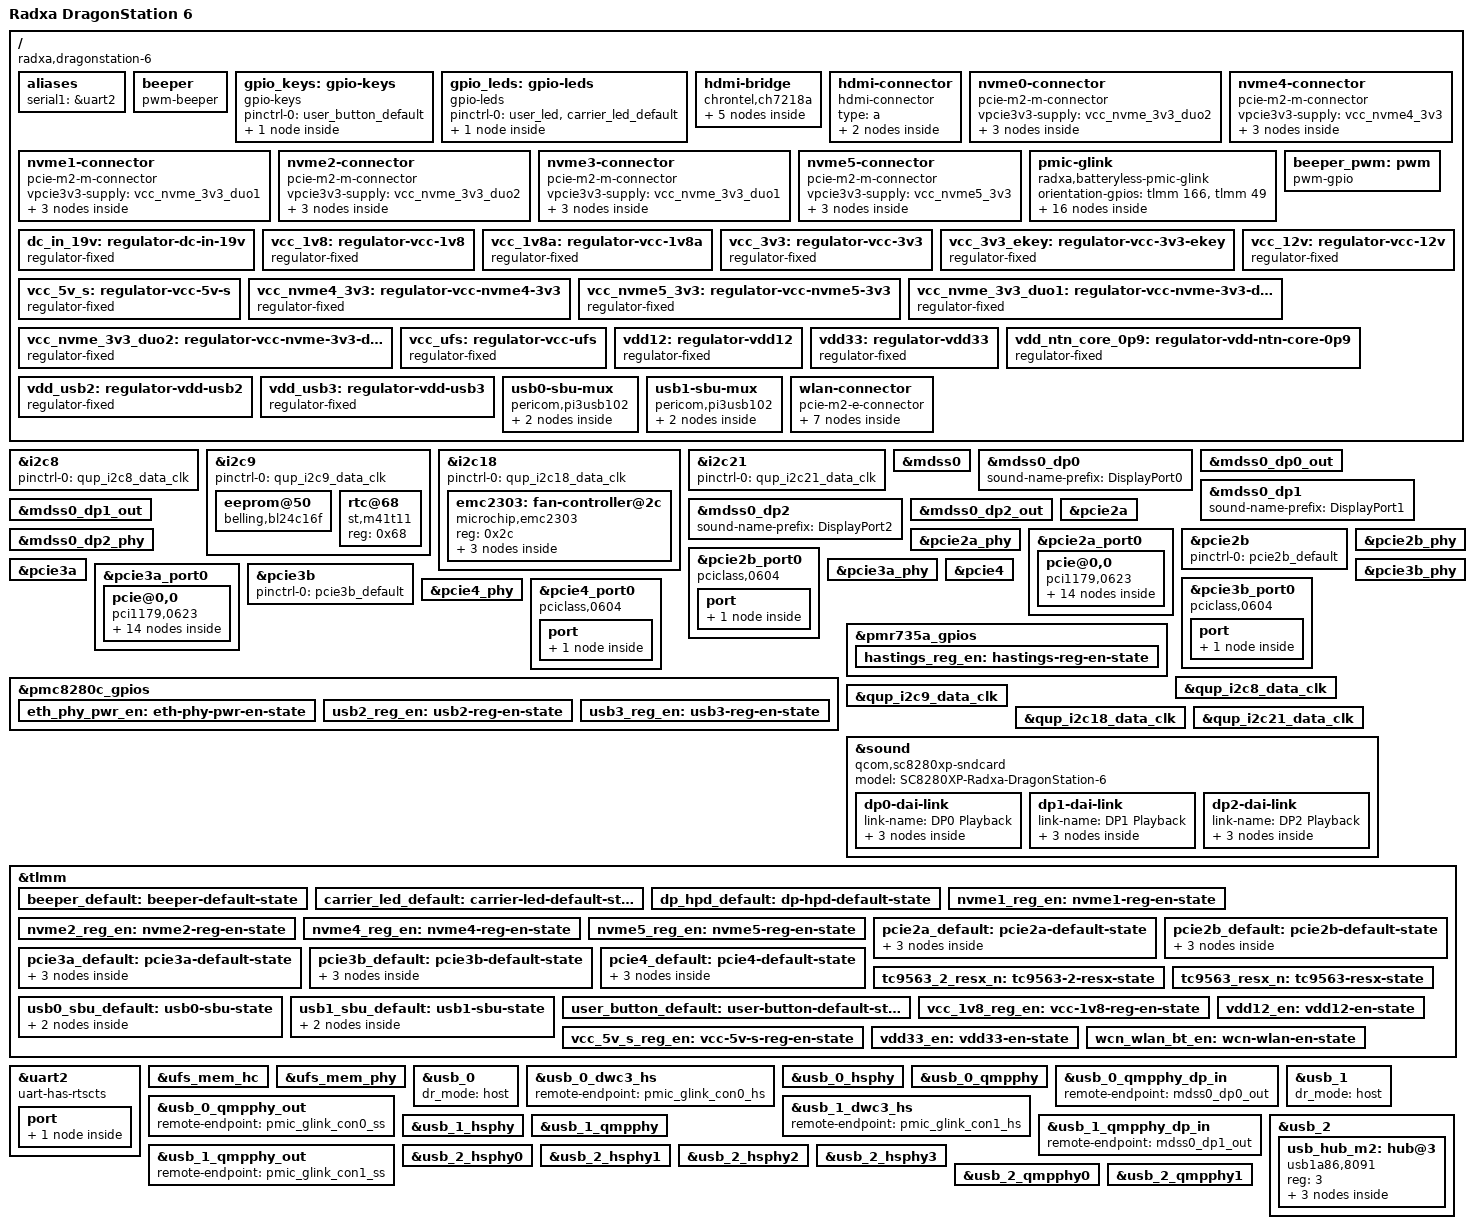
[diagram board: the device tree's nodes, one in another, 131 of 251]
// SPDX-License-Identifier: BSD-3-Clause
/*
 * Copyright (c) 2026 Radxa Computer (Shenzhen) Co., Ltd.
 */

/dts-v1/;

#include <dt-bindings/input/input.h>
#include <dt-bindings/leds/common.h>
#include "sc8280xp-radxa-rcore-q8280.dtsi"

/ {
	model = "Radxa DragonStation 6";
	compatible = "radxa,dragonstation-6", "radxa,rcore-q8280", "qcom,sc8280xp";
	chassis-type = "embedded";

	aliases {
		serial1 = &uart2;
	};

	beeper {
		compatible = "pwm-beeper";
		pwms = <&beeper_pwm 0 500000 0>;
		amp-supply = <&vcc_3v3>;
		beeper-hz = <2000>;
	};

	gpio_keys: gpio-keys {
		compatible = "gpio-keys";
		pinctrl-0 = <&user_button_default>;
		pinctrl-names = "default";

		user-button {
			label = "User Button";
			gpios = <&tlmm 114 GPIO_ACTIVE_LOW>;
			linux,code = <KEY_PROG1>;
			debounce-interval = <20>;
		};
	};

	gpio_leds: gpio-leds {
		compatible = "gpio-leds";
		pinctrl-0 = <&user_led>, <&carrier_led_default>;
		pinctrl-names = "default";

		user-led2 {
			label = "carrier:blue:status";
			color = <LED_COLOR_ID_BLUE>;
			function = LED_FUNCTION_STATUS;
			gpios = <&tlmm 115 GPIO_ACTIVE_HIGH>;
			default-state = "off";
		};
	};

	hdmi-bridge {
		compatible = "chrontel,ch7218a";
		vdd-supply = <&vcc_5v_s>;
		pinctrl-0 = <&dp_hpd_default>;
		pinctrl-names = "default";

		ports {
			#address-cells = <1>;
			#size-cells = <0>;

			port@0 {
				reg = <0>;

				hdmi_bridge_dp_in: endpoint {
					remote-endpoint = <&mdss0_dp2_out>;
				};
			};

			port@1 {
				reg = <1>;

				hdmi_bridge_frl_out: endpoint {
					remote-endpoint = <&hdmi_con>;
				};
			};
		};
	};

	hdmi-connector {
		compatible = "hdmi-connector";
		type = "a";

		port {
			hdmi_con: endpoint {
				remote-endpoint = <&hdmi_bridge_frl_out>;
			};
		};
	};

	/* J27 M-key */
	nvme0-connector {
		compatible = "pcie-m2-m-connector";
		vpcie3v3-supply = <&vcc_nvme_3v3_duo2>;

		ports {
			#address-cells = <1>;
			#size-cells = <0>;

			port@0 {
				reg = <0>;

				nvme0_pcie_ep: endpoint {
					remote-endpoint = <&pcie2b_ep>;
				};
			};
		};
	};

	/* J28 M-key */
	nvme1-connector {
		compatible = "pcie-m2-m-connector";
		vpcie3v3-supply = <&vcc_nvme_3v3_duo1>;

		ports {
			#address-cells = <1>;
			#size-cells = <0>;

			port@0 {
				reg = <0>;

				nvme1_pcie_ep: endpoint {
					remote-endpoint = <&qps615_1_dsp1_ep>;
				};
			};
		};
	};

	/* J29 M-key */
	nvme2-connector {
		compatible = "pcie-m2-m-connector";
		vpcie3v3-supply = <&vcc_nvme_3v3_duo2>;

		ports {
			#address-cells = <1>;
			#size-cells = <0>;

			port@0 {
				reg = <0>;

				nvme2_pcie_ep: endpoint {
					remote-endpoint = <&pcie3b_ep>;
				};
			};
		};
	};

	/* J30 M-key */
	nvme3-connector {
		compatible = "pcie-m2-m-connector";
		vpcie3v3-supply = <&vcc_nvme_3v3_duo1>;

		ports {
			#address-cells = <1>;
			#size-cells = <0>;

			port@0 {
				reg = <0>;

				nvme3_pcie_ep: endpoint {
					remote-endpoint = <&qps615_2_dsp1_ep>;
				};
			};
		};
	};

	/* J31 M-key */
	nvme4-connector {
		compatible = "pcie-m2-m-connector";
		vpcie3v3-supply = <&vcc_nvme4_3v3>;

		ports {
			#address-cells = <1>;
			#size-cells = <0>;

			port@0 {
				reg = <0>;

				nvme4_pcie_ep: endpoint {
					remote-endpoint = <&qps615_2_dsp2_ep>;
				};
			};
		};
	};

	/* J32 M-key */
	nvme5-connector {
		compatible = "pcie-m2-m-connector";
		vpcie3v3-supply = <&vcc_nvme5_3v3>;

		ports {
			#address-cells = <1>;
			#size-cells = <0>;

			port@0 {
				reg = <0>;

				nvme5_pcie_ep: endpoint {
					remote-endpoint = <&qps615_1_dsp2_ep>;
				};
			};
		};
	};

	pmic-glink {
		compatible = "radxa,batteryless-pmic-glink",
			     "qcom,sc8280xp-pmic-glink", "qcom,pmic-glink";
		#address-cells = <1>;
		#size-cells = <0>;
		orientation-gpios = <&tlmm 166 GPIO_ACTIVE_HIGH>,
				    <&tlmm 49 GPIO_ACTIVE_HIGH>;

		connector@0 {
			compatible = "usb-c-connector";
			reg = <0>;
			power-role = "dual";
			data-role = "dual";

			ports {
				#address-cells = <1>;
				#size-cells = <0>;

				port@0 {
					reg = <0>;

					pmic_glink_con0_hs: endpoint {
						remote-endpoint = <&usb_0_dwc3_hs>;
					};
				};

				port@1 {
					reg = <1>;

					pmic_glink_con0_ss: endpoint {
						remote-endpoint = <&usb_0_qmpphy_out>;
					};
				};

				port@2 {
					reg = <2>;

					pmic_glink_con0_sbu: endpoint {
						remote-endpoint = <&usb0_sbu_mux>;
					};
				};
			};
		};

		connector@1 {
			compatible = "usb-c-connector";
			reg = <1>;
			power-role = "dual";
			data-role = "dual";

			ports {
				#address-cells = <1>;
				#size-cells = <0>;

				port@0 {
					reg = <0>;

					pmic_glink_con1_hs: endpoint {
						remote-endpoint = <&usb_1_dwc3_hs>;
					};
				};

				port@1 {
					reg = <1>;

					pmic_glink_con1_ss: endpoint {
						remote-endpoint = <&usb_1_qmpphy_out>;
					};
				};

				port@2 {
					reg = <2>;

					pmic_glink_con1_sbu: endpoint {
						remote-endpoint = <&usb1_sbu_mux>;
					};
				};
			};
		};
	};

	beeper_pwm: pwm {
		compatible = "pwm-gpio";
		gpios = <&tlmm 174 GPIO_ACTIVE_HIGH>;
		#pwm-cells = <3>;
		pinctrl-0 = <&beeper_default>;
		pinctrl-names = "default";
	};

	dc_in_19v: regulator-dc-in-19v {
		compatible = "regulator-fixed";
		regulator-name = "dc_in_19v";
		regulator-min-microvolt = <19000000>;
		regulator-max-microvolt = <19000000>;
		regulator-always-on;
	};

	vcc_1v8: regulator-vcc-1v8 {
		compatible = "regulator-fixed";
		regulator-name = "vcc_1v8";
		regulator-min-microvolt = <1800000>;
		regulator-max-microvolt = <1800000>;
		vin-supply = <&vcc_1v8a>;
		gpio = <&tlmm 161 GPIO_ACTIVE_HIGH>;
		enable-active-high;
		/* Longer delay for I2C pull-up to stabilize */
		startup-delay-us = <50000>;
		pinctrl-0 = <&vcc_1v8_reg_en>;
		pinctrl-names = "default";
	};

	vcc_1v8a: regulator-vcc-1v8a {
		compatible = "regulator-fixed";
		regulator-name = "vcc_1v8a";
		regulator-min-microvolt = <1800000>;
		regulator-max-microvolt = <1800000>;
		gpio = <&pmc8280c_gpios 4 GPIO_ACTIVE_HIGH>;
		enable-active-high;
		regulator-always-on;
		regulator-boot-on;
		startup-delay-us = <1000>;
		pinctrl-0 = <&eth_phy_pwr_en>;
		pinctrl-names = "default";
	};

	vcc_3v3: regulator-vcc-3v3 {
		compatible = "regulator-fixed";
		regulator-name = "vcc_3v3";
		regulator-min-microvolt = <3300000>;
		regulator-max-microvolt = <3300000>;
		regulator-always-on;
	};

	vcc_3v3_ekey: regulator-vcc-3v3-ekey {
		compatible = "regulator-fixed";
		regulator-name = "vcc_3v3_ekey";
		regulator-min-microvolt = <3300000>;
		regulator-max-microvolt = <3300000>;
		gpio = <&pmr735a_gpios 1 GPIO_ACTIVE_HIGH>;
		enable-active-high;
		startup-delay-us = <3000>;
		pinctrl-0 = <&hastings_reg_en>;
		pinctrl-names = "default";
		regulator-boot-on;
	};

	vcc_5v_s: regulator-vcc-5v-s {
		compatible = "regulator-fixed";
		regulator-name = "vcc_5v_s";
		regulator-min-microvolt = <5000000>;
		regulator-max-microvolt = <5000000>;
		gpio = <&tlmm 159 GPIO_ACTIVE_HIGH>;
		enable-active-high;
		startup-delay-us = <250000>;
		off-on-delay-us = <150000>;
		pinctrl-0 = <&vcc_5v_s_reg_en>;
		pinctrl-names = "default";
	};

	vcc_12v: regulator-vcc-12v {
		compatible = "regulator-fixed";
		regulator-name = "vcc_12v";
		regulator-min-microvolt = <12000000>;
		regulator-max-microvolt = <12000000>;
		regulator-always-on;
		vin-supply = <&dc_in_19v>;
	};

	vcc_nvme4_3v3: regulator-vcc-nvme4-3v3 {
		compatible = "regulator-fixed";
		regulator-name = "vcc_nvme4_3v3";
		regulator-min-microvolt = <3300000>;
		regulator-max-microvolt = <3300000>;
		gpio = <&tlmm 201 GPIO_ACTIVE_HIGH>;
		enable-active-high;
		startup-delay-us = <3000>;
		pinctrl-0 = <&nvme4_reg_en>;
		pinctrl-names = "default";
		regulator-boot-on;
		vin-supply = <&vcc_3v3>;
	};

	vcc_nvme5_3v3: regulator-vcc-nvme5-3v3 {
		compatible = "regulator-fixed";
		regulator-name = "vcc_nvme5_3v3";
		regulator-min-microvolt = <3300000>;
		regulator-max-microvolt = <3300000>;
		gpio = <&tlmm 135 GPIO_ACTIVE_HIGH>;
		enable-active-high;
		startup-delay-us = <3000>;
		pinctrl-0 = <&nvme5_reg_en>;
		pinctrl-names = "default";
		regulator-boot-on;
		vin-supply = <&vcc_3v3>;
	};

	vcc_nvme_3v3_duo1: regulator-vcc-nvme-3v3-duo1 {
		compatible = "regulator-fixed";
		regulator-name = "vcc_nvme_3v3_duo1";
		regulator-min-microvolt = <3300000>;
		regulator-max-microvolt = <3300000>;
		gpio = <&tlmm 213 GPIO_ACTIVE_HIGH>;
		enable-active-high;
		startup-delay-us = <3000>;
		pinctrl-0 = <&nvme1_reg_en>;
		pinctrl-names = "default";
		vin-supply = <&dc_in_19v>;
	};

	vcc_nvme_3v3_duo2: regulator-vcc-nvme-3v3-duo2 {
		compatible = "regulator-fixed";
		regulator-name = "vcc_nvme_3v3_duo2";
		regulator-min-microvolt = <3300000>;
		regulator-max-microvolt = <3300000>;
		gpio = <&tlmm 212 GPIO_ACTIVE_HIGH>;
		enable-active-high;
		startup-delay-us = <3000>;
		pinctrl-0 = <&nvme2_reg_en>;
		pinctrl-names = "default";
		vin-supply = <&dc_in_19v>;
	};

	/* This regulator is part of the removable UFS module on J17. */
	vcc_ufs: regulator-vcc-ufs {
		compatible = "regulator-fixed";
		regulator-name = "vcc_ufs";
		regulator-min-microvolt = <2480000>;
		regulator-max-microvolt = <2480000>;
		vin-supply = <&vreg_l7d>;
	};

	vdd12: regulator-vdd12 {
		compatible = "regulator-fixed";
		regulator-name = "vdd12";
		regulator-min-microvolt = <1200000>;
		regulator-max-microvolt = <1200000>;
		gpio = <&tlmm 54 GPIO_ACTIVE_HIGH>;
		enable-active-high;
		startup-delay-us = <1000>;
		pinctrl-0 = <&vdd12_en>;
		pinctrl-names = "default";
		regulator-always-on;
		regulator-boot-on;
		vin-supply = <&vcc_5v_s>;
	};

	vdd33: regulator-vdd33 {
		compatible = "regulator-fixed";
		regulator-name = "vdd33";
		regulator-min-microvolt = <3300000>;
		regulator-max-microvolt = <3300000>;
		gpio = <&tlmm 53 GPIO_ACTIVE_HIGH>;
		enable-active-high;
		startup-delay-us = <1000>;
		pinctrl-0 = <&vdd33_en>;
		pinctrl-names = "default";
		regulator-always-on;
		regulator-boot-on;
		vin-supply = <&vcc_5v_s>;
	};

	vdd_ntn_core_0p9: regulator-vdd-ntn-core-0p9 {
		compatible = "regulator-fixed";
		regulator-name = "vdd_ntn_core_0p9";
		regulator-min-microvolt = <900000>;
		regulator-max-microvolt = <900000>;
		vin-supply = <&vcc_3v3>;
	};

	vdd_usb2: regulator-vdd-usb2 {
		compatible = "regulator-fixed";
		regulator-name = "vdd_usb2";
		regulator-min-microvolt = <5000000>;
		regulator-max-microvolt = <5000000>;
		gpio = <&pmc8280c_gpios 5 GPIO_ACTIVE_HIGH>;
		enable-active-high;
		startup-delay-us = <700>;
		pinctrl-0 = <&usb2_reg_en>;
		pinctrl-names = "default";
		regulator-always-on;
		regulator-boot-on;
	};

	vdd_usb3: regulator-vdd-usb3 {
		compatible = "regulator-fixed";
		regulator-name = "vdd_usb3";
		regulator-min-microvolt = <5000000>;
		regulator-max-microvolt = <5000000>;
		gpio = <&pmc8280c_gpios 6 GPIO_ACTIVE_HIGH>;
		enable-active-high;
		startup-delay-us = <700>;
		pinctrl-0 = <&usb3_reg_en>;
		pinctrl-names = "default";
		regulator-always-on;
		regulator-boot-on;
	};

	usb0-sbu-mux {
		compatible = "pericom,pi3usb102", "gpio-sbu-mux";
		enable-gpios = <&tlmm 101 GPIO_ACTIVE_LOW>;
		select-gpios = <&tlmm 164 GPIO_ACTIVE_HIGH>;
		pinctrl-0 = <&usb0_sbu_default>;
		pinctrl-names = "default";
		mode-switch;
		orientation-switch;

		port {
			usb0_sbu_mux: endpoint {
				remote-endpoint = <&pmic_glink_con0_sbu>;
			};
		};
	};

	usb1-sbu-mux {
		compatible = "pericom,pi3usb102", "gpio-sbu-mux";
		enable-gpios = <&tlmm 48 GPIO_ACTIVE_LOW>;
		select-gpios = <&tlmm 47 GPIO_ACTIVE_HIGH>;
		pinctrl-0 = <&usb1_sbu_default>;
		pinctrl-names = "default";
		mode-switch;
		orientation-switch;

		port {
			usb1_sbu_mux: endpoint {
				remote-endpoint = <&pmic_glink_con1_sbu>;
			};
		};
	};

	wlan-connector {
		compatible = "pcie-m2-e-connector";
		vpcie3v3-supply = <&vcc_3v3_ekey>;
		vpcie1v8-supply = <&vreg_s10b>;
		w-disable1-gpios = <&tlmm 134 GPIO_ACTIVE_LOW>;
		w-disable2-gpios = <&tlmm 133 GPIO_ACTIVE_LOW>;
		uart-wake-gpios = <&tlmm 130 GPIO_ACTIVE_LOW>;
		pinctrl-0 = <&wcn_wlan_bt_en>;
		pinctrl-names = "default";

		ports {
			#address-cells = <1>;
			#size-cells = <0>;

			/* PCIe interface for Wi-Fi */
			port@0 {
				reg = <0>;

				wlan_pcie_ep: endpoint {
					remote-endpoint = <&pcie4_ep>;
				};
			};

			/* USB interface for BT */
			port@2 {
				reg = <2>;

				wlan_usb_ep: endpoint {
					remote-endpoint = <&usb_hub_m2_ep>;
				};
			};

			/* UART interface for BT */
			port@3 {
				reg = <3>;

				wlan_uart_ep: endpoint {
					remote-endpoint = <&uart2_ep>;
				};
			};
		};
	};
};

/* U14 QPS615 Module PCIe Switch */
&i2c8 {
	pinctrl-0 = <&qup_i2c8_data_clk>;
	pinctrl-names = "default";
	status = "okay";
};

&i2c9 {
	pinctrl-0 = <&qup_i2c9_data_clk>;
	pinctrl-names = "default";
	status = "okay";

	eeprom@50 {
		compatible = "belling,bl24c16f", "atmel,24c16";
		reg = <0x50>;
		pagesize = <16>;
		vcc-supply = <&vreg_s10b>;
		wp-gpios = <&tlmm 65 GPIO_ACTIVE_LOW>;
		read-only;
	};

	rtc@68 {
		compatible = "st,m41t11";
		reg = <0x68>;
	};
};

&i2c18 {
	pinctrl-0 = <&qup_i2c18_data_clk>;
	pinctrl-names = "default";
	status = "okay";

	emc2303: fan-controller@2c {
		compatible = "microchip,emc2303", "microchip,emc2305";
		reg = <0x2c>;
		#address-cells = <1>;
		#size-cells = <0>;
		#pwm-cells = <3>;

		cpu_fan: fan@0 {
			reg = <0>;
			pwms = <&emc2303 35000 0 1>;
			#cooling-cells = <2>;
		};

		ssd_fan: fan@1 {
			reg = <1>;
			pwms = <&emc2303 25000 0 1>;
			#cooling-cells = <2>;
		};

		ssd_fan2: fan@2 {
			reg = <2>;
			pwms = <&emc2303 25000 0 1>;
			#cooling-cells = <2>;
		};
	};
};

/* U13 QPS615 Module PCIe Switch */
&i2c21 {
	pinctrl-0 = <&qup_i2c21_data_clk>;
	pinctrl-names = "default";
	status = "okay";
};

&mdss0 {
	status = "okay";
};

&mdss0_dp0 {
	sound-name-prefix = "DisplayPort0";
	status = "okay";
};

&mdss0_dp0_out {
	data-lanes = <0 1 2 3>;
	link-frequencies = /bits/ 64 <1620000000 2700000000 5400000000 8100000000>;
	remote-endpoint = <&usb_0_qmpphy_dp_in>;
};

&mdss0_dp1 {
	sound-name-prefix = "DisplayPort1";
	status = "okay";
};

&mdss0_dp1_out {
	data-lanes = <0 1 2 3>;
	link-frequencies = /bits/ 64 <1620000000 2700000000 5400000000 8100000000>;
	remote-endpoint = <&usb_1_qmpphy_dp_in>;
};

&mdss0_dp2 {
	sound-name-prefix = "DisplayPort2";
	status = "okay";
};

&mdss0_dp2_out {
	data-lanes = <0 1 2 3>;
	link-frequencies = /bits/ 64 <1620000000 2700000000 5400000000 8100000000>;
	remote-endpoint = <&hdmi_bridge_dp_in>;
};

&mdss0_dp2_phy {
	status = "okay";
};

/* U14 QPS615 Module */
&pcie2a {
	num-lanes = <2>;
	pinctrl-0 = <&pcie2a_default>;
	pinctrl-names = "default";
	status = "okay";
};

&pcie2a_phy {
	status = "okay";
};

&pcie2a_port0 {
	reset-gpios = <&tlmm 143 GPIO_ACTIVE_LOW>;
	wake-gpios = <&tlmm 145 GPIO_ACTIVE_LOW>;

	pcie@0,0 {
		compatible = "pci1179,0623";
		reg = <0x10000 0x0 0x0 0x0 0x0>;
		#address-cells = <3>;
		#size-cells = <2>;
		device_type = "pci";
		ranges;
		bus-range = <0x2 0xff>;
		vddc-supply = <&vdd_ntn_core_0p9>;
		vdd18-supply = <&vcc_1v8>;
		vdd09-supply = <&vdd_ntn_core_0p9>;
		vddio1-supply = <&vcc_1v8>;
		vddio2-supply = <&vcc_1v8>;
		vddio18-supply = <&vcc_1v8>;
		i2c-parent = <&i2c8 0x77>;
		resx-gpios = <&tlmm 131 GPIO_ACTIVE_LOW>;
		pinctrl-0 = <&tc9563_2_resx_n>;
		pinctrl-names = "default";

		pcie@1,0 {
			compatible = "pciclass,0604";
			reg = <0x20800 0x0 0x0 0x0 0x0>;
			#address-cells = <3>;
			#size-cells = <2>;
			device_type = "pci";
			ranges;
			bus-range = <0x3 0xff>;
			status = "okay";

			port {
				qps615_2_dsp1_ep: endpoint {
					remote-endpoint = <&nvme3_pcie_ep>;
				};
			};
		};

		pcie@2,0 {
			compatible = "pciclass,0604";
			reg = <0x21000 0x0 0x0 0x0 0x0>;
			#address-cells = <3>;
			#size-cells = <2>;
			device_type = "pci";
			ranges;
			bus-range = <0x4 0xff>;
			status = "okay";

			port {
				qps615_2_dsp2_ep: endpoint {
					remote-endpoint = <&nvme4_pcie_ep>;
				};
			};
		};

		pcie@3,0 {
			compatible = "pciclass,0604";
			reg = <0x21800 0x0 0x0 0x0 0x0>;
			#address-cells = <3>;
			#size-cells = <2>;
			device_type = "pci";
			ranges;
			bus-range = <0x5 0xff>;

			/* No PHY attached for this MAC */
			qps615_2_emac0: pci@0,0 {
				compatible = "pci1179,0220";
				reg = <0x50000 0x0 0x0 0x0 0x0>;
				#address-cells = <3>;
				#size-cells = <2>;
				device_type = "pci";
				ranges;
				gpio-controller;
				#gpio-cells = <2>;
			};

			qps615_2_emac1: pci@0,1 {
				compatible = "pci1179,0220";
				reg = <0x50100 0x0 0x0 0x0 0x0>;
				#address-cells = <3>;
				#size-cells = <2>;
				device_type = "pci";
				ranges;
				phy-mode = "10gbase-r";
				phy-handle = <&qps615_2_emac1_phy>;
				nvmem-cells = <&mac_addr1>;
				nvmem-cell-names = "mac-address";

				mdio {
					compatible = "snps,dwmac-mdio";
					clock-frequency = <10000000>;
					#address-cells = <1>;
					#size-cells = <0>;
					reset-gpios = <&qps615_2_emac0 1 GPIO_ACTIVE_LOW>;
					reset-delay-us = <200000>;
					reset-post-delay-us = <350000>;

					qps615_2_emac1_phy: ethernet-phy@7 {
						compatible = "ethernet-phy-id7500.94a1",
							     "ethernet-phy-ieee802.3-c45";
						reg = <0x7>;
						firmware-name = "as21x1x_fw.bin";

						leds {
							#address-cells = <1>;
							#size-cells = <0>;

							led@0 {
								reg = <0>;
								color = <LED_COLOR_ID_GREEN>;
								function = LED_FUNCTION_ACTIVITY;
								default-state = "keep";
							};

							led@1 {
								reg = <1>;
								color = <LED_COLOR_ID_YELLOW>;
								function = LED_FUNCTION_LAN;
								default-state = "keep";
							};
						};
					};
				};
			};
		};
	};
};

/* J27 M-KEY */
&pcie2b {
	pinctrl-0 = <&pcie2b_default>;
	pinctrl-names = "default";
	status = "okay";
};

&pcie2b_phy {
	status = "okay";
};

&pcie2b_port0 {
	compatible = "pciclass,0604";
	reset-gpios = <&tlmm 147 GPIO_ACTIVE_LOW>;
	wake-gpios = <&tlmm 146 GPIO_ACTIVE_LOW>;

	port {
		pcie2b_ep: endpoint {
			remote-endpoint = <&nvme0_pcie_ep>;
		};
	};
};

/* U13 QPS615 Module */
&pcie3a {
	num-lanes = <2>;
	pinctrl-0 = <&pcie3a_default>;
	pinctrl-names = "default";
	status = "okay";
};

&pcie3a_phy {
	status = "okay";
};

&pcie3a_port0 {
	reset-gpios = <&tlmm 151 GPIO_ACTIVE_LOW>;
	wake-gpios = <&tlmm 148 GPIO_ACTIVE_LOW>;

	pcie@0,0 {
		compatible = "pci1179,0623";
		reg = <0x10000 0x0 0x0 0x0 0x0>;
		#address-cells = <3>;
		#size-cells = <2>;
		device_type = "pci";
		ranges;
		bus-range = <0x2 0xff>;
		vddc-supply = <&vdd_ntn_core_0p9>;
		vdd18-supply = <&vcc_1v8>;
		vdd09-supply = <&vdd_ntn_core_0p9>;
		vddio1-supply = <&vcc_1v8>;
		vddio2-supply = <&vcc_1v8>;
		vddio18-supply = <&vcc_1v8>;
		i2c-parent = <&i2c21 0x77>;
		resx-gpios = <&tlmm 108 GPIO_ACTIVE_LOW>;
		pinctrl-0 = <&tc9563_resx_n>;
		pinctrl-names = "default";

		pcie@1,0 {
			compatible = "pciclass,0604";
			reg = <0x20800 0x0 0x0 0x0 0x0>;
			#address-cells = <3>;
			#size-cells = <2>;
			device_type = "pci";
			ranges;
			bus-range = <0x3 0xff>;
			status = "okay";

			port {
				qps615_1_dsp1_ep: endpoint {
					remote-endpoint = <&nvme1_pcie_ep>;
				};
			};
		};

		pcie@2,0 {
			compatible = "pciclass,0604";
			reg = <0x21000 0x0 0x0 0x0 0x0>;
			#address-cells = <3>;
			#size-cells = <2>;
			device_type = "pci";
			ranges;
			bus-range = <0x4 0xff>;
			status = "okay";

			port {
				qps615_1_dsp2_ep: endpoint {
					remote-endpoint = <&nvme5_pcie_ep>;
				};
			};
		};

		pcie@3,0 {
			compatible = "pciclass,0604";
			reg = <0x21800 0x0 0x0 0x0 0x0>;
			#address-cells = <3>;
			#size-cells = <2>;
			device_type = "pci";
			ranges;
			bus-range = <0x5 0xff>;

			/* No PHY attached for this MAC */
			qps615_1_emac0: pci@0,0 {
				compatible = "pci1179,0220";
				reg = <0x50000 0x0 0x0 0x0 0x0>;
				#address-cells = <3>;
				#size-cells = <2>;
				device_type = "pci";
				ranges;
				gpio-controller;
				#gpio-cells = <2>;
			};

			qps615_1_emac1: pci@0,1 {
				compatible = "pci1179,0220";
				reg = <0x50100 0x0 0x0 0x0 0x0>;
				#address-cells = <3>;
				#size-cells = <2>;
				device_type = "pci";
				ranges;
				phy-mode = "10gbase-r";
				phy-handle = <&qps615_1_emac1_phy>;
				nvmem-cells = <&mac_addr0>;
				nvmem-cell-names = "mac-address";

				mdio {
					compatible = "snps,dwmac-mdio";
					clock-frequency = <10000000>;
					#address-cells = <1>;
					#size-cells = <0>;
					reset-gpios = <&qps615_1_emac0 1 GPIO_ACTIVE_LOW>;
					reset-delay-us = <200000>;
					reset-post-delay-us = <350000>;

					qps615_1_emac1_phy: ethernet-phy@7 {
						compatible = "ethernet-phy-id7500.94a1",
							     "ethernet-phy-ieee802.3-c45";
						reg = <0x7>;
						firmware-name = "as21x1x_fw.bin";

						leds {
							#address-cells = <1>;
							#size-cells = <0>;

							led@0 {
								reg = <0>;
								color = <LED_COLOR_ID_GREEN>;
								function = LED_FUNCTION_ACTIVITY;
								default-state = "keep";
							};

							led@1 {
								reg = <1>;
								color = <LED_COLOR_ID_YELLOW>;
								function = LED_FUNCTION_LAN;
								default-state = "keep";
							};
						};
					};
				};
			};
		};
	};
};

/* J29 M-KEY */
&pcie3b {
	pinctrl-0 = <&pcie3b_default>;
	pinctrl-names = "default";
	status = "okay";
};

&pcie3b_phy {
	status = "okay";
};

&pcie3b_port0 {
	compatible = "pciclass,0604";
	reset-gpios = <&tlmm 153 GPIO_ACTIVE_LOW>;
	wake-gpios = <&tlmm 149 GPIO_ACTIVE_LOW>;

	port {
		pcie3b_ep: endpoint {
			remote-endpoint = <&nvme2_pcie_ep>;
		};
	};
};

/* J18 E-KEY */
&pcie4 {
	vddpe-3v3-supply = <&vcc_3v3_ekey>;
	pinctrl-0 = <&pcie4_default>;
	pinctrl-names = "default";
	status = "okay";
};

&pcie4_phy {
	status = "okay";
};

&pcie4_port0 {
	compatible = "pciclass,0604";
	reset-gpios = <&tlmm 141 GPIO_ACTIVE_LOW>;
	wake-gpios = <&tlmm 139 GPIO_ACTIVE_LOW>;

	port {
		pcie4_ep: endpoint {
			remote-endpoint = <&wlan_pcie_ep>;
		};
	};
};

&pmc8280c_gpios {
	eth_phy_pwr_en: eth-phy-pwr-en-state {
		pins = "gpio4";
		function = "normal";
	};

	usb2_reg_en: usb2-reg-en-state {
		pins = "gpio5";
		function = "normal";
	};

	usb3_reg_en: usb3-reg-en-state {
		pins = "gpio6";
		function = "normal";
	};
};

&pmr735a_gpios {
	hastings_reg_en: hastings-reg-en-state {
		pins = "gpio1";
		function = "normal";
	};
};

&qup_i2c8_data_clk {
	drive-strength = <2>;
	bias-disable;
};

&qup_i2c9_data_clk {
	drive-strength = <2>;
	bias-disable;
};

&qup_i2c18_data_clk {
	drive-strength = <2>;
	bias-disable;
};

&qup_i2c21_data_clk {
	drive-strength = <2>;
	bias-disable;
};

&sound {
	compatible = "qcom,sc8280xp-sndcard";
	model = "SC8280XP-Radxa-DragonStation-6";

	dp0-dai-link {
		link-name = "DP0 Playback";

		codec {
			sound-dai = <&mdss0_dp0>;
		};

		cpu {
			sound-dai = <&q6apmbedai DISPLAY_PORT_RX_0>;
		};

		platform {
			sound-dai = <&q6apm>;
		};
	};

	dp1-dai-link {
		link-name = "DP1 Playback";

		codec {
			sound-dai = <&mdss0_dp1>;
		};

		cpu {
			sound-dai = <&q6apmbedai DISPLAY_PORT_RX_1>;
		};

		platform {
			sound-dai = <&q6apm>;
		};
	};

	dp2-dai-link {
		link-name = "DP2 Playback";

		codec {
			sound-dai = <&mdss0_dp2>;
		};

		cpu {
			sound-dai = <&q6apmbedai DISPLAY_PORT_RX_2>;
		};

		platform {
			sound-dai = <&q6apm>;
		};
	};
};

&tlmm {
	beeper_default: beeper-default-state {
		pins = "gpio174";
		function = "gpio";
		drive-strength = <2>;
		bias-disable;
	};

	carrier_led_default: carrier-led-default-state {
		pins = "gpio115";
		function = "gpio";
		bias-pull-up;
	};

	dp_hpd_default: dp-hpd-default-state {
		pins = "gpio2";
		function = "edp_hot";
		bias-disable;
	};

	nvme1_reg_en: nvme1-reg-en-state {
		pins = "gpio213";
		function = "gpio";
		drive-strength = <2>;
		bias-disable;
	};

	nvme2_reg_en: nvme2-reg-en-state {
		pins = "gpio212";
		function = "gpio";
		drive-strength = <2>;
		bias-disable;
	};

	nvme4_reg_en: nvme4-reg-en-state {
		pins = "gpio201";
		function = "gpio";
		drive-strength = <2>;
		bias-disable;
	};

	nvme5_reg_en: nvme5-reg-en-state {
		pins = "gpio135";
		function = "gpio";
		drive-strength = <2>;
		bias-disable;
	};

	pcie2a_default: pcie2a-default-state {
		clkreq-n-pins {
			pins = "gpio142";
			function = "pcie2a_clkreq";
			drive-strength = <2>;
			bias-pull-up;
		};

		perst-n-pins {
			pins = "gpio143";
			function = "gpio";
			drive-strength = <2>;
			bias-disable;
		};

		wake-n-pins {
			pins = "gpio145";
			function = "gpio";
			drive-strength = <2>;
			bias-pull-up;
		};
	};

	pcie2b_default: pcie2b-default-state {
		clkreq-n-pins {
			pins = "gpio144";
			function = "pcie2b_clkreq";
			drive-strength = <2>;
			bias-pull-up;
		};

		perst-n-pins {
			pins = "gpio147";
			function = "gpio";
			drive-strength = <2>;
			bias-disable;
		};

		wake-n-pins {
			pins = "gpio146";
			function = "gpio";
			drive-strength = <2>;
			bias-pull-up;
		};
	};

	pcie3a_default: pcie3a-default-state {
		clkreq-n-pins {
			pins = "gpio150";
			function = "pcie3a_clkreq";
			drive-strength = <2>;
			bias-pull-up;
		};

		perst-n-pins {
			pins = "gpio151";
			function = "gpio";
			drive-strength = <2>;
			bias-disable;
		};

		wake-n-pins {
			pins = "gpio148";
			function = "gpio";
			drive-strength = <2>;
			bias-pull-up;
		};
	};

	pcie3b_default: pcie3b-default-state {
		clkreq-n-pins {
			pins = "gpio152";
			function = "pcie3b_clkreq";
			drive-strength = <2>;
			bias-pull-up;
		};

		perst-n-pins {
			pins = "gpio153";
			function = "gpio";
			drive-strength = <2>;
			bias-pull-down;
		};

		wake-n-pins {
			pins = "gpio149";
			function = "gpio";
			drive-strength = <2>;
			bias-pull-up;
		};
	};

	pcie4_default: pcie4-default-state {
		clkreq-n-pins {
			pins = "gpio140";
			function = "pcie4_clkreq";
			drive-strength = <2>;
			bias-pull-up;
		};

		perst-n-pins {
			pins = "gpio141";
			function = "gpio";
			drive-strength = <2>;
			bias-disable;
		};

		wake-n-pins {
			pins = "gpio139";
			function = "gpio";
			drive-strength = <2>;
			bias-pull-up;
		};
	};

	tc9563_2_resx_n: tc9563-2-resx-state {
		pins = "gpio131";
		function = "gpio";
		drive-strength = <2>;
		bias-disable;
	};

	tc9563_resx_n: tc9563-resx-state {
		pins = "gpio108";
		function = "gpio";
		drive-strength = <2>;
		bias-disable;
	};

	usb0_sbu_default: usb0-sbu-state {
		oe-n-pins {
			pins = "gpio101";
			function = "gpio";
			bias-disable;
			drive-strength = <16>;
			output-high;
		};

		sel-pins {
			pins = "gpio164";
			function = "gpio";
			bias-disable;
			drive-strength = <16>;
		};
	};

	usb1_sbu_default: usb1-sbu-state {
		oe-n-pins {
			pins = "gpio48";
			function = "gpio";
			bias-disable;
			drive-strength = <16>;
			output-high;
		};

		sel-pins {
			pins = "gpio47";
			function = "gpio";
			bias-disable;
			drive-strength = <16>;
		};
	};

	user_button_default: user-button-default-state {
		pins = "gpio114";
		function = "gpio";
		drive-strength = <2>;
		bias-pull-up;
	};

	vcc_1v8_reg_en: vcc-1v8-reg-en-state {
		pins = "gpio161";
		function = "gpio";
		drive-strength = <2>;
		bias-disable;
	};

	vcc_5v_s_reg_en: vcc-5v-s-reg-en-state {
		pins = "gpio159";
		function = "gpio";
		drive-strength = <2>;
		bias-disable;
	};

	vdd12_en: vdd12-en-state {
		pins = "gpio54";
		function = "gpio";
		drive-strength = <2>;
		bias-disable;
	};

	vdd33_en: vdd33-en-state {
		pins = "gpio53";
		function = "gpio";
		drive-strength = <2>;
		bias-disable;
	};

	wcn_wlan_bt_en: wcn-wlan-en-state {
		pins = "gpio133", "gpio134";
		function = "gpio";
		drive-strength = <2>;
		bias-disable;
	};
};

/* E-key Bluetooth */
&uart2 {
	uart-has-rtscts;
	status = "okay";

	port {
		uart2_ep: endpoint {
			remote-endpoint = <&wlan_uart_ep>;
		};
	};
};

&ufs_mem_hc {
	reset-gpios = <&tlmm 228 GPIO_ACTIVE_LOW>;
	vcc-supply = <&vcc_ufs>;
	vcc-max-microamp = <1100000>;
	vccq-supply = <&vreg_l3d>;
	vccq-max-microamp = <1200000>;
	limit-hs-gear = <3>;
	status = "okay";
};

&ufs_mem_phy {
	status = "okay";
};

&usb_0 {
	status = "okay";
	dr_mode = "host";
};

&usb_0_dwc3_hs {
	remote-endpoint = <&pmic_glink_con0_hs>;
};

&usb_0_hsphy {
	status = "okay";
};

&usb_0_qmpphy {
	mode-switch;
	orientation-switch;
	status = "okay";
};

&usb_0_qmpphy_dp_in {
	remote-endpoint = <&mdss0_dp0_out>;
};

&usb_0_qmpphy_out {
	remote-endpoint = <&pmic_glink_con0_ss>;
};

&usb_1 {
	status = "okay";
	dr_mode = "host";
};

&usb_1_dwc3_hs {
	remote-endpoint = <&pmic_glink_con1_hs>;
};

&usb_1_hsphy {
	status = "okay";
};

&usb_1_qmpphy {
	mode-switch;
	orientation-switch;
	status = "okay";
};

&usb_1_qmpphy_dp_in {
	remote-endpoint = <&mdss0_dp1_out>;
};

&usb_1_qmpphy_out {
	remote-endpoint = <&pmic_glink_con1_ss>;
};

&usb_2 {
	status = "okay";
	#address-cells = <1>;
	#size-cells = <0>;

	usb_hub_m2: hub@3 {
		compatible = "usb1a86,8091";
		reg = <3>;

		ports {
			#address-cells = <1>;
			#size-cells = <0>;

			port@2 {
				reg = <2>;

				usb_hub_m2_ep: endpoint {
					remote-endpoint = <&wlan_usb_ep>;
				};
			};
		};
	};
};

&usb_2_hsphy0 {
	status = "okay";
};

&usb_2_hsphy1 {
	status = "okay";
};

&usb_2_hsphy2 {
	status = "okay";
};

&usb_2_hsphy3 {
	status = "okay";
};

&usb_2_qmpphy0 {
	status = "okay";
};

&usb_2_qmpphy1 {
	status = "okay";
};
